VERSION "2027-draft-2026-10-22"

NS_ :

BS_:

BU_: BPSLeader ElconInterface
VAL_TABLE_ EnableDisable 1 "Enabled" 0 "Disabled" ;
VAL_TABLE_ OnOff 1 "On" 0 "Off" ;
VAL_TABLE_ FaultState 1 "Fault" 0 "OK" ;
VAL_TABLE_ WarningState 1 "Warning" 0 "NoWarning" ;
VAL_TABLE_ DeviceStatus 2 "Waiting" 1 "Fault" 0 "OK" ;
VAL_TABLE_ Permission 1 "Allowed" 0 "NotAllowed" ;
VAL_TABLE_ Connection 1 "Connected" 0 "Disconnected" ;
VAL_TABLE_ Pressed 1 "Pressed" 0 "NotPressed" ;
VAL_TABLE_ Validity 1 "Valid" 0 "Invalid" ;
VAL_TABLE_ Watchdog 1 "TimedOut" 0 "Alive" ;
VAL_TABLE_ NormalAdvanced 1 "Advanced" 0 "Normal" ;
VAL_TABLE_ MotorCommandSource 1 "External" 0 "VCU" ;
VAL_TABLE_ Gear 3 "Invalid" 2 "Reverse" 1 "Forward" 0 "Neutral" ;
VAL_TABLE_ BPSFaultSummary 5 "SMBFault" 4 "PrechargeFault" 3 "ContactorRelayFault" 2 "EmergencyStop" 1 "SetpointFault" 0 "OK" ;
VAL_TABLE_ VCUState 7 "VehicleNotReady" 6 "Disabled" 5 "CruiseControl" 4 "Regen" 3 "ReverseDrive" 2 "NeutralDrive" 1 "ForwardDrive" 0 "Init" ;
VAL_TABLE_ ChargeState 2 "Charging" 1 "Standby" 0 "Disabled" ;
VAL_TABLE_ EVSEState 5 "F_EVSEFault" 4 "E_Fault" 3 "D_VentilationRequired" 2 "C_ChargingReady" 1 "B_Connected" 0 "A_Disconnected" ;
VAL_TABLE_ GPSAntennaState 3 "Unknown" 2 "ShortCircuit" 1 "OpenCircuit" 0 "OK" ;
VAL_TABLE_ GPSFix 2 "Fix3D" 1 "Fix2D" 0 "NoFix" ;
VAL_TABLE_ CellularTechnology 4 "Other" 3 "NB_IoT" 2 "LTE_M" 1 "LTE" 0 "None" ;
VAL_TABLE_ TPEEControlMode 2 "ConstantInputVoltage" 1 "PerturbAndObserve" 0 "Disabled" ;
VAL_TABLE_ TPEEOperatingMode 7 "Fault" 6 "MinimumInputVoltage" 5 "TemperatureDerating" 4 "ConstantOutputCurrent" 3 "ConstantOutputVoltage" 2 "MinimumInputCurrent" 1 "ConstantInputCurrent" 0 "ConstantInputVoltage" ;
VAL_TABLE_ TPEEFault 8 "Fault" 7 "PhaseOverCurrent" 6 "InputUnderCurrent" 5 "InputOverCurrent" 4 "OutputOverCurrent" 3 "OutputOverVoltage" 2 "InputOverVoltage" 1 "ConfigurationError" 0 "OK" ;
VAL_TABLE_ LWSCalibration 1 "Calibrated" 0 "NotCalibrated" ;
VAL_TABLE_ LWSTrim 1 "Trimmed" 0 "NotTrimmed" ;
VAL_TABLE_ LWSCommand 5 "ResetCalibration" 3 "SetAngleZero" ;
VAL_TABLE_ ElconControl 1 "Disable" 0 "Charge" ;
VAL_TABLE_ ElconMuxPage 5 "Page5" 4 "Page4" 3 "Page3" 2 "Page2" 1 "Page1" ;

BO_ 96 BPSLeaderStatus: 32 BPSLeader
 SG_ Status : 0|2@1+ (1,0) [0.0|3.0] ""  ElconInterface
 SG_ FaultSummary : 2|3@1+ (1,0) [0.0|7.0] ""  ElconInterface
 SG_ FaultOverTemperature : 8|1@1+ (1,0) [0.0|1.0] ""  ElconInterface
 SG_ FaultOverVoltage : 9|1@1+ (1,0) [0.0|1.0] ""  ElconInterface
 SG_ FaultUnderVoltage : 10|1@1+ (1,0) [0.0|1.0] ""  ElconInterface
 SG_ FaultChargeOverCurrent : 11|1@1+ (1,0) [0.0|1.0] ""  ElconInterface
 SG_ FaultDischargeOverCurrent : 12|1@1+ (1,0) [0.0|1.0] ""  ElconInterface
 SG_ FaultHVPositiveContactorMismatch : 13|1@1+ (1,0) [0.0|1.0] ""  ElconInterface
 SG_ FaultMotorContactorMismatch : 14|1@1+ (1,0) [0.0|1.0] ""  ElconInterface
 SG_ FaultHVNegativeContactorMismatch : 15|1@1+ (1,0) [0.0|1.0] ""  ElconInterface
 SG_ FaultMainPrechargeRelayMismatch : 16|1@1+ (1,0) [0.0|1.0] ""  ElconInterface
 SG_ FaultMotorPrechargeRelayMismatch : 17|1@1+ (1,0) [0.0|1.0] ""  ElconInterface
 SG_ FaultDriverEstop : 18|1@1+ (1,0) [0.0|1.0] ""  ElconInterface
 SG_ FaultExternalEstop : 19|1@1+ (1,0) [0.0|1.0] ""  ElconInterface
 SG_ FaultBatteryEstop : 20|1@1+ (1,0) [0.0|1.0] ""  ElconInterface
 SG_ FaultChargerEstop : 21|1@1+ (1,0) [0.0|1.0] ""  ElconInterface
 SG_ FaultMainPrechargeTimeout : 22|1@1+ (1,0) [0.0|1.0] ""  ElconInterface
 SG_ FaultMotorPrechargeTimeout : 23|1@1+ (1,0) [0.0|1.0] ""  ElconInterface
 SG_ FaultMainVoltageNotPresent : 24|1@1+ (1,0) [0.0|1.0] ""  ElconInterface
 SG_ FaultMotorVoltageNotPresent : 25|1@1+ (1,0) [0.0|1.0] ""  ElconInterface
 SG_ WarningSMBCommunication : 32|1@1+ (1,0) [0.0|1.0] ""  ElconInterface
 SG_ WarningUnderVoltage : 33|1@1+ (1,0) [0.0|1.0] ""  ElconInterface
 SG_ WarningOverVoltage : 34|1@1+ (1,0) [0.0|1.0] ""  ElconInterface
 SG_ WarningChargeOverTemperature : 35|1@1+ (1,0) [0.0|1.0] ""  ElconInterface
 SG_ WarningDischargeOverTemperature : 36|1@1+ (1,0) [0.0|1.0] ""  ElconInterface
 SG_ WarningBatteryFan1 : 37|1@1+ (1,0) [0.0|1.0] ""  ElconInterface
 SG_ WarningBatteryFan2 : 38|1@1+ (1,0) [0.0|1.0] ""  ElconInterface
 SG_ WarningBPSFan : 39|1@1+ (1,0) [0.0|1.0] ""  ElconInterface
 SG_ DriveOK : 40|1@1+ (1,0) [0.0|1.0] ""  ElconInterface
 SG_ ChargeOK : 41|1@1+ (1,0) [0.0|1.0] ""  ElconInterface
 SG_ MPPTSetMode : 42|2@1+ (1,0) [0.0|3.0] ""  ElconInterface
 SG_ ElconChargeOK : 44|1@1+ (1,0) [0.0|1.0] ""  ElconInterface
 SG_ RegenChargeOK : 45|1@1+ (1,0) [0.0|1.0] ""  ElconInterface
 SG_ HVPositiveContactor : 46|1@1+ (1,0) [0.0|1.0] ""  ElconInterface
 SG_ MotorContactor : 47|1@1+ (1,0) [0.0|1.0] ""  ElconInterface
 SG_ HVNegativeContactor : 48|1@1+ (1,0) [0.0|1.0] ""  ElconInterface
 SG_ MainPrechargeRelay : 49|1@1+ (1,0) [0.0|1.0] ""  ElconInterface
 SG_ MotorPrechargeRelay : 50|1@1+ (1,0) [0.0|1.0] ""  ElconInterface
 SG_ MainBatteryVoltage : 56|12@1+ (0.05,0) [0.0|204.75] "V"  ElconInterface
 SG_ MotorBatteryVoltage : 68|12@1+ (0.05,0) [0.0|204.75] "V"  ElconInterface
 SG_ MainVoltage : 80|12@1+ (0.05,0) [0.0|204.75] "V"  ElconInterface
 SG_ MotorVoltage : 92|12@1+ (0.05,0) [0.0|204.75] "V"  ElconInterface
 SG_ MaxBatteryTemperature : 104|11@1+ (0.05,0) [0.0|102.35] "degC"  ElconInterface
 SG_ AverageBatteryTemperature : 115|11@1+ (0.05,0) [0.0|102.35] "degC"  ElconInterface
 SG_ BatteryCurrent : 126|14@1+ (0.01,-50) [-50.0|113.83] "A"  ElconInterface
 SG_ MinCellVoltage : 140|12@1+ (1,2000) [2000.0|6095.0] "mV"  ElconInterface
 SG_ MaxCellVoltage : 152|12@1+ (1,2000) [2000.0|6095.0] "mV"  ElconInterface
 SG_ MPPTVoltageLimit : 164|16@1+ (0.05,0) [0|175] "V"  ElconInterface
 SG_ MPPTCurrentLimit : 180|16@1+ (0.01,0) [0|16.38] "A"  ElconInterface
 SG_ BatteryFan1Tach : 196|12@1+ (5,0) [0.0|20475.0] "rpm"  ElconInterface
 SG_ BatteryFan2Tach : 208|12@1+ (5,0) [0.0|20475.0] "rpm"  ElconInterface
 SG_ BPSFanTach : 220|12@1+ (5,0) [0.0|20475.0] "rpm"  ElconInterface

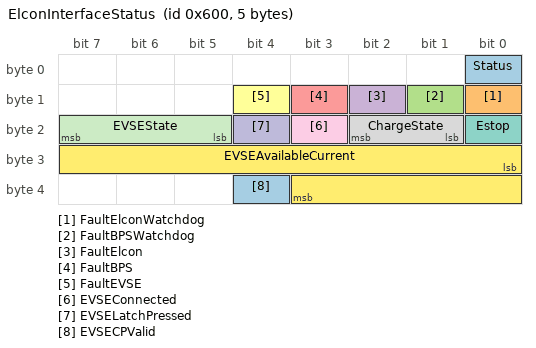
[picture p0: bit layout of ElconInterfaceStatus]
BO_ 1536 ElconInterfaceStatus: 5 ElconInterface
 SG_ Status : 0|1@1+ (1,0) [0.0|1.0] ""  BPSLeader
 SG_ FaultElconWatchdog : 8|1@1+ (1,0) [0.0|1.0] ""  BPSLeader
 SG_ FaultBPSWatchdog : 9|1@1+ (1,0) [0.0|1.0] ""  BPSLeader
 SG_ FaultElcon : 10|1@1+ (1,0) [0.0|1.0] ""  BPSLeader
 SG_ FaultBPS : 11|1@1+ (1,0) [0.0|1.0] ""  BPSLeader
 SG_ FaultEVSE : 12|1@1+ (1,0) [0.0|1.0] ""  BPSLeader
 SG_ Estop : 16|1@1+ (1,0) [0.0|1.0] ""  BPSLeader
 SG_ ChargeState : 17|2@1+ (1,0) [0.0|3.0] ""  BPSLeader
 SG_ EVSEConnected : 19|1@1+ (1,0) [0.0|1.0] ""  BPSLeader
 SG_ EVSELatchPressed : 20|1@1+ (1,0) [0.0|1.0] ""  BPSLeader
 SG_ EVSEState : 21|3@1+ (1,0) [0.0|7.0] ""  BPSLeader
 SG_ EVSEAvailableCurrent : 24|12@1+ (0.01,0) [0|25.5] "A"  BPSLeader
 SG_ EVSECPValid : 36|1@1+ (1,0) [0.0|1.0] ""  BPSLeader

CM_ BO_ 96 "Critical BPS status. Bitmaps are expanded into individual named bits. Battery current preserves uint14, 0.01 A/bit and -50 A offset. MPPTInterface translates standardized limits into vendor command encodings; hardware/firmware limits must still be enforced.";
CM_ SG_ 96 BPSFanTach "BPSFanTach";
CM_ SG_ 96 BatteryFan2Tach "BatteryFan2Tach";
CM_ SG_ 96 BatteryFan1Tach "BatteryFan1Tach";
CM_ SG_ 96 MPPTCurrentLimit "MPPTCurrentLimit";
CM_ SG_ 96 MPPTVoltageLimit "MPPTVoltageLimit";
CM_ SG_ 96 MaxCellVoltage "MaxCellVoltage";
CM_ SG_ 96 MinCellVoltage "MinCellVoltage";
CM_ SG_ 96 BatteryCurrent "BatteryCurrent";
CM_ SG_ 96 AverageBatteryTemperature "AverageBatteryTemperature";
CM_ SG_ 96 MaxBatteryTemperature "MaxBatteryTemperature";
CM_ SG_ 96 MotorVoltage "MotorVoltage";
CM_ SG_ 96 MainVoltage "MainVoltage";
CM_ SG_ 96 MotorBatteryVoltage "MotorBatteryVoltage";
CM_ SG_ 96 MainBatteryVoltage "MainBatteryVoltage";
CM_ SG_ 96 MotorPrechargeRelay "MotorPrechargeRelay";
CM_ SG_ 96 MainPrechargeRelay "MainPrechargeRelay";
CM_ SG_ 96 HVNegativeContactor "HVNegativeContactor";
CM_ SG_ 96 MotorContactor "MotorContactor";
CM_ SG_ 96 HVPositiveContactor "HVPositiveContactor";
CM_ SG_ 96 RegenChargeOK "RegenChargeOK";
CM_ SG_ 96 ElconChargeOK "ElconChargeOK";
CM_ SG_ 96 MPPTSetMode "MPPTSetMode";
CM_ SG_ 96 ChargeOK "ChargeOK";
CM_ SG_ 96 DriveOK "DriveOK";
CM_ SG_ 96 WarningBPSFan "WarningBPSFan";
CM_ SG_ 96 WarningBatteryFan2 "WarningBatteryFan2";
CM_ SG_ 96 WarningBatteryFan1 "WarningBatteryFan1";
CM_ SG_ 96 WarningDischargeOverTemperature "WarningDischargeOverTemperature";
CM_ SG_ 96 WarningChargeOverTemperature "WarningChargeOverTemperature";
CM_ SG_ 96 WarningOverVoltage "WarningOverVoltage";
CM_ SG_ 96 WarningUnderVoltage "WarningUnderVoltage";
CM_ SG_ 96 WarningSMBCommunication "WarningSMBCommunication";
CM_ SG_ 96 FaultMotorVoltageNotPresent "FaultMotorVoltageNotPresent";
CM_ SG_ 96 FaultMainVoltageNotPresent "FaultMainVoltageNotPresent";
CM_ SG_ 96 FaultMotorPrechargeTimeout "FaultMotorPrechargeTimeout";
CM_ SG_ 96 FaultMainPrechargeTimeout "FaultMainPrechargeTimeout";
CM_ SG_ 96 FaultChargerEstop "FaultChargerEstop";
CM_ SG_ 96 FaultBatteryEstop "FaultBatteryEstop";
CM_ SG_ 96 FaultExternalEstop "FaultExternalEstop";
CM_ SG_ 96 FaultDriverEstop "FaultDriverEstop";
CM_ SG_ 96 FaultMotorPrechargeRelayMismatch "FaultMotorPrechargeRelayMismatch";
CM_ SG_ 96 FaultMainPrechargeRelayMismatch "FaultMainPrechargeRelayMismatch";
CM_ SG_ 96 FaultHVNegativeContactorMismatch "FaultHVNegativeContactorMismatch";
CM_ SG_ 96 FaultMotorContactorMismatch "FaultMotorContactorMismatch";
CM_ SG_ 96 FaultHVPositiveContactorMismatch "FaultHVPositiveContactorMismatch";
CM_ SG_ 96 FaultDischargeOverCurrent "FaultDischargeOverCurrent";
CM_ SG_ 96 FaultChargeOverCurrent "FaultChargeOverCurrent";
CM_ SG_ 96 FaultUnderVoltage "FaultUnderVoltage";
CM_ SG_ 96 FaultOverVoltage "FaultOverVoltage";
CM_ SG_ 96 FaultOverTemperature "FaultOverTemperature";
CM_ SG_ 96 FaultSummary "FaultSummary";
CM_ SG_ 96 Status "Status";
CM_ BO_ 1536 "2027 team-defined layout; physical values use the shared scaling conventions.";
CM_ SG_ 1536 EVSECPValid "EVSECPValid";
CM_ SG_ 1536 EVSEAvailableCurrent "EVSEAvailableCurrent";
CM_ SG_ 1536 EVSEState "EVSEState";
CM_ SG_ 1536 EVSELatchPressed "EVSELatchPressed";
CM_ SG_ 1536 EVSEConnected "EVSEConnected";
CM_ SG_ 1536 ChargeState "ChargeState";
CM_ SG_ 1536 Estop "Estop";
CM_ SG_ 1536 FaultEVSE "FaultEVSE";
CM_ SG_ 1536 FaultBPS "FaultBPS";
CM_ SG_ 1536 FaultElcon "FaultElcon";
CM_ SG_ 1536 FaultBPSWatchdog "FaultBPSWatchdog";
CM_ SG_ 1536 FaultElconWatchdog "FaultElconWatchdog";
CM_ SG_ 1536 Status "Status";
BA_DEF_ SG_  "ValueTable" STRING ;
BA_DEF_ BO_  "LayoutPending" INT 0 1;
BA_DEF_ BO_  "ProtocolSource" STRING ;
BA_DEF_  "BusType" STRING ;
BA_DEF_  "DBName" STRING ;
BA_DEF_ BO_  "VFrameFormat" ENUM  "StandardCAN","ExtendedCAN","reserved","J1939PG","reserved","reserved","reserved","reserved","reserved","reserved","reserved","reserved","reserved","reserved","StandardCAN_FD","ExtendedCAN_FD";
BA_DEF_ BO_  "CANFD_BRS" ENUM  "0","1";
BA_DEF_DEF_  "ValueTable" "";
BA_DEF_DEF_  "LayoutPending" 0;
BA_DEF_DEF_  "ProtocolSource" "";
BA_DEF_DEF_  "BusType" "CAN";
BA_DEF_DEF_  "DBName" "";
BA_DEF_DEF_  "VFrameFormat" "StandardCAN";
BA_DEF_DEF_  "CANFD_BRS" "1";
BA_ "BusType" "CAN FD";
BA_ "DBName" "ChargerCAN";
BA_ "ProtocolSource" BO_ 96 "2027 allocation draft";
BA_ "VFrameFormat" BO_ 96 14;
BA_ "ValueTable" SG_ 96 MotorPrechargeRelay "OnOff";
BA_ "ValueTable" SG_ 96 MainPrechargeRelay "OnOff";
BA_ "ValueTable" SG_ 96 HVNegativeContactor "OnOff";
BA_ "ValueTable" SG_ 96 MotorContactor "OnOff";
BA_ "ValueTable" SG_ 96 HVPositiveContactor "OnOff";
BA_ "ValueTable" SG_ 96 RegenChargeOK "Permission";
BA_ "ValueTable" SG_ 96 ElconChargeOK "Permission";
BA_ "ValueTable" SG_ 96 MPPTSetMode "TPEEControlMode";
BA_ "ValueTable" SG_ 96 ChargeOK "Permission";
BA_ "ValueTable" SG_ 96 DriveOK "Permission";
BA_ "ValueTable" SG_ 96 WarningBPSFan "WarningState";
BA_ "ValueTable" SG_ 96 WarningBatteryFan2 "WarningState";
BA_ "ValueTable" SG_ 96 WarningBatteryFan1 "WarningState";
BA_ "ValueTable" SG_ 96 WarningDischargeOverTemperature "WarningState";
BA_ "ValueTable" SG_ 96 WarningChargeOverTemperature "WarningState";
BA_ "ValueTable" SG_ 96 WarningOverVoltage "WarningState";
BA_ "ValueTable" SG_ 96 WarningUnderVoltage "WarningState";
BA_ "ValueTable" SG_ 96 WarningSMBCommunication "WarningState";
BA_ "ValueTable" SG_ 96 FaultMotorVoltageNotPresent "FaultState";
BA_ "ValueTable" SG_ 96 FaultMainVoltageNotPresent "FaultState";
BA_ "ValueTable" SG_ 96 FaultMotorPrechargeTimeout "FaultState";
BA_ "ValueTable" SG_ 96 FaultMainPrechargeTimeout "FaultState";
BA_ "ValueTable" SG_ 96 FaultChargerEstop "FaultState";
BA_ "ValueTable" SG_ 96 FaultBatteryEstop "FaultState";
BA_ "ValueTable" SG_ 96 FaultExternalEstop "FaultState";
BA_ "ValueTable" SG_ 96 FaultDriverEstop "FaultState";
BA_ "ValueTable" SG_ 96 FaultMotorPrechargeRelayMismatch "FaultState";
BA_ "ValueTable" SG_ 96 FaultMainPrechargeRelayMismatch "FaultState";
BA_ "ValueTable" SG_ 96 FaultHVNegativeContactorMismatch "FaultState";
BA_ "ValueTable" SG_ 96 FaultMotorContactorMismatch "FaultState";
BA_ "ValueTable" SG_ 96 FaultHVPositiveContactorMismatch "FaultState";
BA_ "ValueTable" SG_ 96 FaultDischargeOverCurrent "FaultState";
BA_ "ValueTable" SG_ 96 FaultChargeOverCurrent "FaultState";
BA_ "ValueTable" SG_ 96 FaultUnderVoltage "FaultState";
BA_ "ValueTable" SG_ 96 FaultOverVoltage "FaultState";
BA_ "ValueTable" SG_ 96 FaultOverTemperature "FaultState";
BA_ "ValueTable" SG_ 96 FaultSummary "BPSFaultSummary";
BA_ "ValueTable" SG_ 96 Status "DeviceStatus";
BA_ "ProtocolSource" BO_ 1536 "2027 allocation draft";
BA_ "VFrameFormat" BO_ 1536 14;
BA_ "ValueTable" SG_ 1536 EVSECPValid "Validity";
BA_ "ValueTable" SG_ 1536 EVSEState "EVSEState";
BA_ "ValueTable" SG_ 1536 EVSELatchPressed "Pressed";
BA_ "ValueTable" SG_ 1536 EVSEConnected "Connection";
BA_ "ValueTable" SG_ 1536 ChargeState "ChargeState";
BA_ "ValueTable" SG_ 1536 Estop "Pressed";
BA_ "ValueTable" SG_ 1536 FaultEVSE "FaultState";
BA_ "ValueTable" SG_ 1536 FaultBPS "FaultState";
BA_ "ValueTable" SG_ 1536 FaultElcon "FaultState";
BA_ "ValueTable" SG_ 1536 FaultBPSWatchdog "FaultState";
BA_ "ValueTable" SG_ 1536 FaultElconWatchdog "FaultState";
BA_ "ValueTable" SG_ 1536 Status "FaultState";
VAL_ 96 MotorPrechargeRelay 0 "Off" 1 "On" ;
VAL_ 96 MainPrechargeRelay 0 "Off" 1 "On" ;
VAL_ 96 HVNegativeContactor 0 "Off" 1 "On" ;
VAL_ 96 MotorContactor 0 "Off" 1 "On" ;
VAL_ 96 HVPositiveContactor 0 "Off" 1 "On" ;
VAL_ 96 RegenChargeOK 0 "NotAllowed" 1 "Allowed" ;
VAL_ 96 ElconChargeOK 0 "NotAllowed" 1 "Allowed" ;
VAL_ 96 MPPTSetMode 0 "Disabled" 1 "PerturbAndObserve" 2 "ConstantInputVoltage" ;
VAL_ 96 ChargeOK 0 "NotAllowed" 1 "Allowed" ;
VAL_ 96 DriveOK 0 "NotAllowed" 1 "Allowed" ;
VAL_ 96 WarningBPSFan 0 "NoWarning" 1 "Warning" ;
VAL_ 96 WarningBatteryFan2 0 "NoWarning" 1 "Warning" ;
VAL_ 96 WarningBatteryFan1 0 "NoWarning" 1 "Warning" ;
VAL_ 96 WarningDischargeOverTemperature 0 "NoWarning" 1 "Warning" ;
VAL_ 96 WarningChargeOverTemperature 0 "NoWarning" 1 "Warning" ;
VAL_ 96 WarningOverVoltage 0 "NoWarning" 1 "Warning" ;
VAL_ 96 WarningUnderVoltage 0 "NoWarning" 1 "Warning" ;
VAL_ 96 WarningSMBCommunication 0 "NoWarning" 1 "Warning" ;
VAL_ 96 FaultMotorVoltageNotPresent 0 "OK" 1 "Fault" ;
VAL_ 96 FaultMainVoltageNotPresent 0 "OK" 1 "Fault" ;
VAL_ 96 FaultMotorPrechargeTimeout 0 "OK" 1 "Fault" ;
VAL_ 96 FaultMainPrechargeTimeout 0 "OK" 1 "Fault" ;
VAL_ 96 FaultChargerEstop 0 "OK" 1 "Fault" ;
VAL_ 96 FaultBatteryEstop 0 "OK" 1 "Fault" ;
VAL_ 96 FaultExternalEstop 0 "OK" 1 "Fault" ;
VAL_ 96 FaultDriverEstop 0 "OK" 1 "Fault" ;
VAL_ 96 FaultMotorPrechargeRelayMismatch 0 "OK" 1 "Fault" ;
VAL_ 96 FaultMainPrechargeRelayMismatch 0 "OK" 1 "Fault" ;
VAL_ 96 FaultHVNegativeContactorMismatch 0 "OK" 1 "Fault" ;
VAL_ 96 FaultMotorContactorMismatch 0 "OK" 1 "Fault" ;
VAL_ 96 FaultHVPositiveContactorMismatch 0 "OK" 1 "Fault" ;
VAL_ 96 FaultDischargeOverCurrent 0 "OK" 1 "Fault" ;
VAL_ 96 FaultChargeOverCurrent 0 "OK" 1 "Fault" ;
VAL_ 96 FaultUnderVoltage 0 "OK" 1 "Fault" ;
VAL_ 96 FaultOverVoltage 0 "OK" 1 "Fault" ;
VAL_ 96 FaultOverTemperature 0 "OK" 1 "Fault" ;
VAL_ 96 FaultSummary 0 "OK" 1 "SetpointFault" 2 "EmergencyStop" 3 "ContactorRelayFault" 4 "PrechargeFault" 5 "SMBFault" ;
VAL_ 96 Status 0 "OK" 1 "Fault" 2 "Waiting" ;
VAL_ 1536 EVSECPValid 0 "Invalid" 1 "Valid" ;
VAL_ 1536 EVSEState 0 "A_Disconnected" 1 "B_Connected" 2 "C_ChargingReady" 3 "D_VentilationRequired" 4 "E_Fault" 5 "F_EVSEFault" ;
VAL_ 1536 EVSELatchPressed 0 "NotPressed" 1 "Pressed" ;
VAL_ 1536 EVSEConnected 0 "Disconnected" 1 "Connected" ;
VAL_ 1536 ChargeState 0 "Disabled" 1 "Standby" 2 "Charging" ;
VAL_ 1536 Estop 0 "NotPressed" 1 "Pressed" ;
VAL_ 1536 FaultEVSE 0 "OK" 1 "Fault" ;
VAL_ 1536 FaultBPS 0 "OK" 1 "Fault" ;
VAL_ 1536 FaultElcon 0 "OK" 1 "Fault" ;
VAL_ 1536 FaultBPSWatchdog 0 "OK" 1 "Fault" ;
VAL_ 1536 FaultElconWatchdog 0 "OK" 1 "Fault" ;
VAL_ 1536 Status 0 "OK" 1 "Fault" ;
